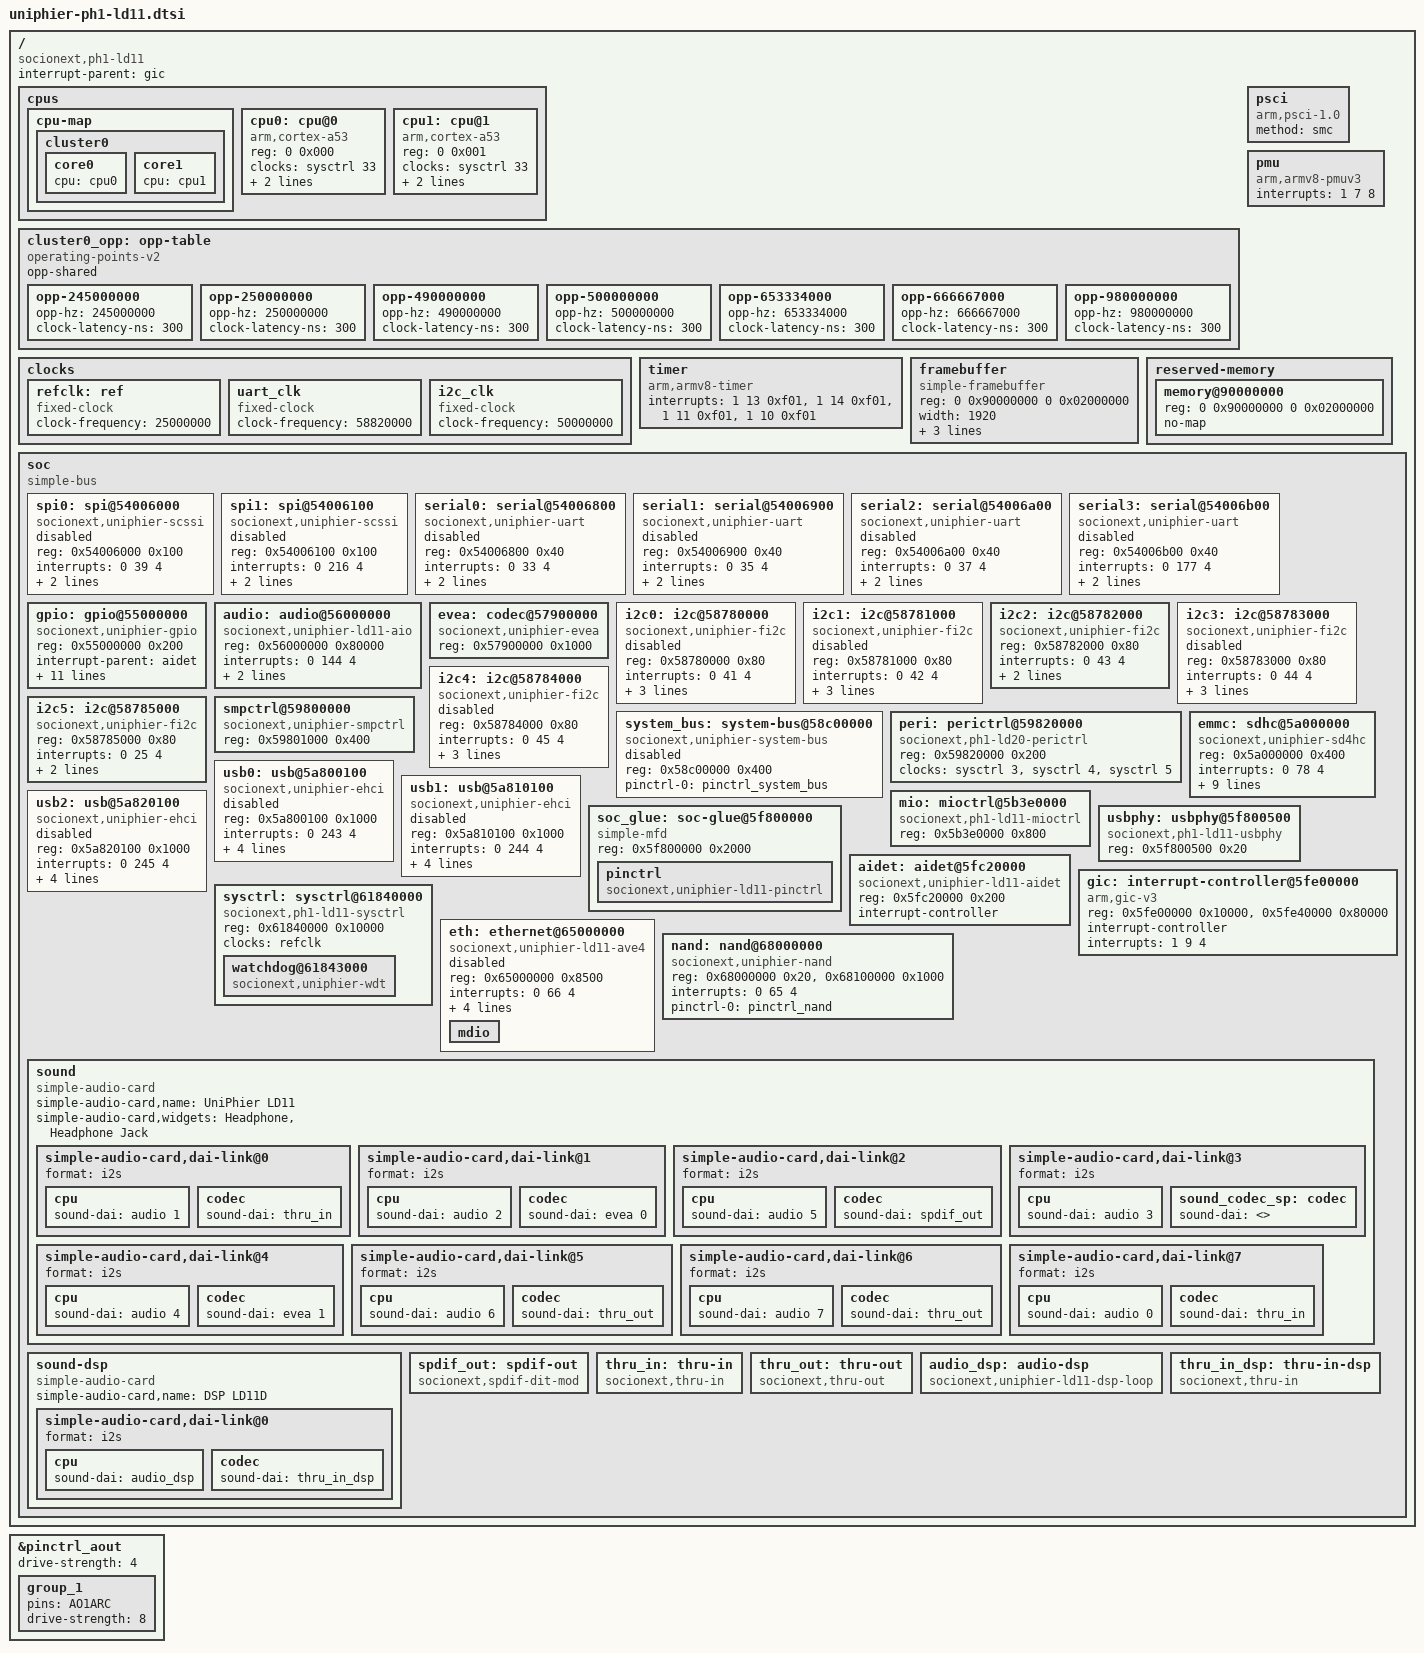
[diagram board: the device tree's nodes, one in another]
// SPDX-Lincense-Identfier: GPL-2.0+ OR MIT
//
// Device Tree Source for UniPhier PH1-LD11 SoC
//
// Copyright (C) 2016 Socionext Inc.
//   Author: Masahiro Yamada <yamada.masahiro@socionext.com>

#include <dt-bindings/gpio/gpio.h>
#include <dt-bindings/gpio/uniphier-gpio.h>

/memreserve/ 0x80000000 0x02000000;

/ {
	compatible = "socionext,ph1-ld11";
	#address-cells = <2>;
	#size-cells = <2>;
	interrupt-parent = <&gic>;

	cpus {
		#address-cells = <2>;
		#size-cells = <0>;

		cpu-map {
			cluster0 {
				core0 {
					cpu = <&cpu0>;
				};
				core1 {
					cpu = <&cpu1>;
				};
			};
		};

		cpu0: cpu@0 {
			device_type = "cpu";
			compatible = "arm,cortex-a53", "arm,armv8";
			reg = <0 0x000>;
			clocks = <&sysctrl 33>;
			enable-method = "psci";
			operating-points-v2 = <&cluster0_opp>;
		};

		cpu1: cpu@1 {
			device_type = "cpu";
			compatible = "arm,cortex-a53", "arm,armv8";
			reg = <0 0x001>;
			clocks = <&sysctrl 33>;
			enable-method = "psci";
			operating-points-v2 = <&cluster0_opp>;
		};
	};

	cluster0_opp: opp-table {
		compatible = "operating-points-v2";
		opp-shared;

		opp-245000000 {
			opp-hz = /bits/ 64 <245000000>;
			clock-latency-ns = <300>;
		};
		opp-250000000 {
			opp-hz = /bits/ 64 <250000000>;
			clock-latency-ns = <300>;
		};
		opp-490000000 {
			opp-hz = /bits/ 64 <490000000>;
			clock-latency-ns = <300>;
		};
		opp-500000000 {
			opp-hz = /bits/ 64 <500000000>;
			clock-latency-ns = <300>;
		};
		opp-653334000 {
			opp-hz = /bits/ 64 <653334000>;
			clock-latency-ns = <300>;
		};
		opp-666667000 {
			opp-hz = /bits/ 64 <666667000>;
			clock-latency-ns = <300>;
		};
		opp-980000000 {
			opp-hz = /bits/ 64 <980000000>;
			clock-latency-ns = <300>;
		};
	};

	psci {
		compatible = "arm,psci-1.0";
		method = "smc";
	};

	clocks {
		refclk: ref {
			#clock-cells = <0>;
			compatible = "fixed-clock";
			clock-frequency = <25000000>;
		};

		uart_clk: uart_clk {
			#clock-cells = <0>;
			compatible = "fixed-clock";
			clock-frequency = <58820000>;
		};

		i2c_clk: i2c_clk {
			#clock-cells = <0>;
			compatible = "fixed-clock";
			clock-frequency = <50000000>;
		};
	};

	timer {
		compatible = "arm,armv8-timer";
		interrupts = <1 13 0xf01>,
			     <1 14 0xf01>,
			     <1 11 0xf01>,
			     <1 10 0xf01>;
	};

	pmu {
		compatible = "arm,armv8-pmuv3";
		interrupts = <1 7 8>;
	};

	framebuffer {
		compatible = "simple-framebuffer";
		reg = <0 0x90000000 0 0x02000000>;
		width = <1920>;
		height = <1088>;
		stride = <7680>;
		format = "a8r8g8b8";
	};

	reserved-memory {
		#address-cells = <2>;
		#size-cells = <2>;
		ranges;

		memory@90000000 {
			reg = <0 0x90000000 0 0x02000000>;
			no-map;
		};
	};

	soc: soc {
		compatible = "simple-bus";
		#address-cells = <1>;
		#size-cells = <1>;
		ranges = <0 0 0 0xffffffff>;

		spi0: spi@54006000 {
			compatible = "socionext,uniphier-scssi";
			status = "disabled";
			reg = <0x54006000 0x100>;
			interrupts = <0 39 4>;
			pinctrl-names = "default";
			pinctrl-0 = <&pinctrl_spi0>;
			clocks = <&peri 11>;
		};

		spi1: spi@54006100 {
			compatible = "socionext,uniphier-scssi";
			status = "disabled";
			reg = <0x54006100 0x100>;
			interrupts = <0 216 4>;
			pinctrl-names = "default";
			pinctrl-0 = <&pinctrl_spi1>;
			clocks = <&peri 11>;
		};

		serial0: serial@54006800 {
			compatible = "socionext,uniphier-uart";
			status = "disabled";
			reg = <0x54006800 0x40>;
			interrupts = <0 33 4>;
			pinctrl-names = "default";
			pinctrl-0 = <&pinctrl_uart0>;
			clocks = <&peri 0>;
		};

		serial1: serial@54006900 {
			compatible = "socionext,uniphier-uart";
			status = "disabled";
			reg = <0x54006900 0x40>;
			interrupts = <0 35 4>;
			pinctrl-names = "default";
			pinctrl-0 = <&pinctrl_uart1>;
			clocks = <&peri 1>;
		};

		serial2: serial@54006a00 {
			compatible = "socionext,uniphier-uart";
			status = "disabled";
			reg = <0x54006a00 0x40>;
			interrupts = <0 37 4>;
			pinctrl-names = "default";
			pinctrl-0 = <&pinctrl_uart2>;
			clocks = <&peri 2>;
		};

		serial3: serial@54006b00 {
			compatible = "socionext,uniphier-uart";
			status = "disabled";
			reg = <0x54006b00 0x40>;
			interrupts = <0 177 4>;
			pinctrl-names = "default";
			pinctrl-0 = <&pinctrl_uart3>;
			clocks = <&peri 3>;
		};

		gpio: gpio@55000000 {
			compatible = "socionext,uniphier-gpio";
			reg = <0x55000000 0x200>;
			interrupt-parent = <&aidet>;
			interrupt-controller;
			#interrupt-cells = <2>;
			gpio-controller;
			#gpio-cells = <2>;
			gpio-ranges = <&pinctrl 0 0 0>,
				      <&pinctrl 43 0 0>,
				      <&pinctrl 51 0 0>,
				      <&pinctrl 96 0 0>,
				      <&pinctrl 160 0 0>,
				      <&pinctrl 184 0 0>;
			gpio-ranges-group-names = "gpio_range0",
						  "gpio_range1",
						  "gpio_range2",
						  "gpio_range3",
						  "gpio_range4",
						  "gpio_range5";
			ngpios = <200>;
			socionext,interrupt-ranges = <0 48 16>, <16 154 5>,
						     <21 217 3>;
		};

		audio: audio@56000000 {
			compatible = "socionext,uniphier-ld11-aio";
			reg = <0x56000000 0x80000>;
			interrupts = <0 144 4>;
			pinctrl-names = "default";
			pinctrl-0 = <&pinctrl_aout>;
			#sound-dai-cells = <1>;
			socionext,syscon = <&soc_glue>;
		};

		evea: codec@57900000 {
			compatible = "socionext,uniphier-evea";
			reg = <0x57900000 0x1000>;
			#sound-dai-cells = <1>;
		};

		i2c0: i2c@58780000 {
			compatible = "socionext,uniphier-fi2c";
			status = "disabled";
			reg = <0x58780000 0x80>;
			#address-cells = <1>;
			#size-cells = <0>;
			interrupts = <0 41 4>;
			pinctrl-names = "default";
			pinctrl-0 = <&pinctrl_i2c0>;
			clocks = <&peri 4>;
			clock-frequency = <100000>;
		};

		i2c1: i2c@58781000 {
			compatible = "socionext,uniphier-fi2c";
			status = "disabled";
			reg = <0x58781000 0x80>;
			#address-cells = <1>;
			#size-cells = <0>;
			interrupts = <0 42 4>;
			pinctrl-names = "default";
			pinctrl-0 = <&pinctrl_i2c1>;
			clocks = <&peri 5>;
			clock-frequency = <100000>;
		};

		i2c2: i2c@58782000 {
			compatible = "socionext,uniphier-fi2c";
			reg = <0x58782000 0x80>;
			#address-cells = <1>;
			#size-cells = <0>;
			interrupts = <0 43 4>;
			clocks = <&peri 6>;
			clock-frequency = <100000>;
		};

		i2c3: i2c@58783000 {
			compatible = "socionext,uniphier-fi2c";
			status = "disabled";
			reg = <0x58783000 0x80>;
			#address-cells = <1>;
			#size-cells = <0>;
			interrupts = <0 44 4>;
			pinctrl-names = "default";
			pinctrl-0 = <&pinctrl_i2c3>;
			clocks = <&peri 7>;
			clock-frequency = <100000>;
		};

		i2c4: i2c@58784000 {
			compatible = "socionext,uniphier-fi2c";
			status = "disabled";
			reg = <0x58784000 0x80>;
			#address-cells = <1>;
			#size-cells = <0>;
			interrupts = <0 45 4>;
			pinctrl-names = "default";
			pinctrl-0 = <&pinctrl_i2c4>;
			clocks = <&peri 8>;
			clock-frequency = <100000>;
		};

		i2c5: i2c@58785000 {
			compatible = "socionext,uniphier-fi2c";
			reg = <0x58785000 0x80>;
			#address-cells = <1>;
			#size-cells = <0>;
			interrupts = <0 25 4>;
			clocks = <&peri 9>;
			clock-frequency = <400000>;
		};

		system_bus: system-bus@58c00000 {
			compatible = "socionext,uniphier-system-bus";
			status = "disabled";
			reg = <0x58c00000 0x400>;
			#address-cells = <2>;
			#size-cells = <1>;
			pinctrl-names = "default";
			pinctrl-0 = <&pinctrl_system_bus>;
		};

		smpctrl@59800000 {
			compatible = "socionext,uniphier-smpctrl";
			reg = <0x59801000 0x400>;
		};

		peri: perictrl@59820000 {
			compatible = "socionext,ph1-ld20-perictrl";
			reg = <0x59820000 0x200>;
			#clock-cells = <1>;
			clock-names = "uart", "fi2c", "spi";
			clocks = <&sysctrl 3>, <&sysctrl 4>, <&sysctrl 5>;
		};

		emmc: sdhc@5a000000 {
			compatible = "socionext,uniphier-sd4hc", "cdns,sd4hc";
			reg = <0x5a000000 0x400>;
			interrupts = <0 78 4>;
			pinctrl-names = "default";
			pinctrl-0 = <&pinctrl_emmc_1v8>;
			clocks = <&refclk>; /* fake */
			bus-width = <8>;
			mmc-hs200-1_8v;
			cdns,phy-input-delay-legacy = <9>;
			cdns,phy-input-delay-mmc-highspeed = <2>;
			cdns,phy-input-delay-mmc-ddr = <3>;
			cdns,phy-dll-delay-sdclk = <21>;
			cdns,phy-dll-delay-sdclk-hsmmc = <21>;
		};

		usb0: usb@5a800100 {
			compatible = "socionext,uniphier-ehci", "generic-ehci";
			status = "disabled";
			reg = <0x5a800100 0x1000>;
			interrupts = <0 243 4>;
			pinctrl-names = "default";
			pinctrl-0 = <&pinctrl_usb0>;
			clocks = <&mio 4>, <&mio 8>, <&sysctrl 22>;
			phys = <&usbphy>;
			phy-names = "usb";
			has-transaction-translator;
		};

		usb1: usb@5a810100 {
			compatible = "socionext,uniphier-ehci", "generic-ehci";
			status = "disabled";
			reg = <0x5a810100 0x1000>;
			interrupts = <0 244 4>;
			pinctrl-names = "default";
			pinctrl-0 = <&pinctrl_usb1>;
			clocks = <&mio 5>, <&mio 8>, <&sysctrl 22>;
			phys = <&usbphy>;
			phy-names = "usb";
			has-transaction-translator;
		};

		usb2: usb@5a820100 {
			compatible = "socionext,uniphier-ehci", "generic-ehci";
			status = "disabled";
			reg = <0x5a820100 0x1000>;
			interrupts = <0 245 4>;
			pinctrl-names = "default";
			pinctrl-0 = <&pinctrl_usb2>;
			clocks = <&mio 6>, <&mio 8>, <&sysctrl 23>;
			phys = <&usbphy>;
			phy-names = "usb";
			has-transaction-translator;
		};

		mio: mioctrl@5b3e0000 {
			compatible = "socionext,ph1-ld11-mioctrl";
			reg = <0x5b3e0000 0x800>;
			#clock-cells = <1>;
		};

		soc_glue: soc-glue@5f800000 {
			compatible = "simple-mfd", "syscon";
			reg = <0x5f800000 0x2000>;

			pinctrl: pinctrl {
				 compatible = "socionext,uniphier-ld11-pinctrl";
			};
		};

		usbphy: usbphy@5f800500 {
			#phy-cells = <0>;
			compatible = "socionext,ph1-ld11-usbphy";
			reg = <0x5f800500 0x20>;
		};

		aidet: aidet@5fc20000 {
			compatible = "socionext,uniphier-ld11-aidet";
			reg = <0x5fc20000 0x200>;
			interrupt-controller;
			#interrupt-cells = <2>;
		};

		gic: interrupt-controller@5fe00000 {
			compatible = "arm,gic-v3";
			reg = <0x5fe00000 0x10000>,	/* GICD */
			      <0x5fe40000 0x80000>;	/* GICR */
			interrupt-controller;
			#interrupt-cells = <3>;
			interrupts = <1 9 4>;
		};

		sysctrl: sysctrl@61840000 {
			compatible = "socionext,ph1-ld11-sysctrl",
				     "simple-mfd", "syscon";
			reg = <0x61840000 0x10000>;
			#clock-cells = <1>;
			clock-names = "ref";
			clocks = <&refclk>;

			watchdog@61843000 {
				compatible = "socionext,uniphier-wdt";
			};
		};

		eth: ethernet@65000000 {
			compatible = "socionext,uniphier-ld11-ave4";
			status = "disabled";
			reg = <0x65000000 0x8500>;
			interrupts = <0 66 4>;
			clock-names = "ether";
			clocks = <&sysctrl 8>;
			phy-mode = "internal";
			local-mac-address = [00 00 00 00 00 00];
			socionext,syscon-phy-mode = <&soc_glue 0>;

			mdio: mdio {
				#address-cells = <1>;
				#size-cells = <0>;
			};
		};

		nand: nand@68000000 {
			compatible = "socionext,uniphier-nand";
			reg = <0x68000000 0x20>, <0x68100000 0x1000>;
			reg-names = "nand_data", "nand_reg";
			interrupts = <0 65 4>;
			pinctrl-names = "default";
			pinctrl-0 = <&pinctrl_nand>;
		};

		sound {
			compatible = "simple-audio-card";
			simple-audio-card,name = "UniPhier LD11";
			simple-audio-card,widgets = "Headphone", "Headphone Jack";

			simple-audio-card,dai-link@0 {
				/* SIF in 1 */
				format = "i2s";
				cpu {
					sound-dai = <&audio 1>;
				};
				codec {
					sound-dai = <&thru_in>;
				};
			};
			simple-audio-card,dai-link@1 {
				/* Line in/out 1 */
				format = "i2s";
				cpu {
					sound-dai = <&audio 2>;
				};
				codec {
					sound-dai = <&evea 0>;
				};
			};
			simple-audio-card,dai-link@2 {
				/* SPDIF */
				format = "i2s";
				cpu {
					sound-dai = <&audio 5>;
				};
				codec {
					sound-dai = <&spdif_out>;
				};
			};
			simple-audio-card,dai-link@3 {
				/* Speaker */
				format = "i2s";
				cpu {
					sound-dai = <&audio 3>;
				};
				sound_codec_sp: codec {
					/* external codec */
					sound-dai = <>;
				};
			};
			simple-audio-card,dai-link@4 {
				/* Headphone */
				format = "i2s";
				cpu {
					sound-dai = <&audio 4>;
				};
				codec {
					sound-dai = <&evea 1>;
				};
			};
			simple-audio-card,dai-link@5 {
				/* SRC0 */
				format = "i2s";
				cpu {
					sound-dai = <&audio 6>;
				};
				codec {
					sound-dai = <&thru_out>;
				};
			};
			simple-audio-card,dai-link@6 {
				/* SRC1 */
				format = "i2s";
				cpu {
					sound-dai = <&audio 7>;
				};
				codec {
					sound-dai = <&thru_out>;
				};
			};
			simple-audio-card,dai-link@7 {
				/* HDMI in/out */
				format = "i2s";
				cpu {
					sound-dai = <&audio 0>;
				};
				codec {
					sound-dai = <&thru_in>;
				};
			};
		};

		sound-dsp {
			compatible = "simple-audio-card";
			simple-audio-card,name = "DSP LD11D";

			simple-audio-card,dai-link@0 {
				/* BT in */
				format = "i2s";
				cpu {
					sound-dai = <&audio_dsp>;
				};
				codec {
					sound-dai = <&thru_in_dsp>;
				};
			};
		};

		spdif_out: spdif-out {
			compatible = "socionext,spdif-dit-mod";
			#sound-dai-cells = <0>;
		};

		thru_in: thru-in {
			compatible = "socionext,thru-in";
			#sound-dai-cells = <0>;
		};

		thru_out: thru-out {
			compatible = "socionext,thru-out";
			#sound-dai-cells = <0>;
		};

		audio_dsp: audio-dsp {
			compatible = "socionext,uniphier-ld11-dsp-loop";
			#sound-dai-cells = <0>;
		};

		thru_in_dsp: thru-in-dsp {
			compatible = "socionext,thru-in";
			#sound-dai-cells = <0>;
		};
	};
};

#include "uniphier-pinctrl.dtsi"

&pinctrl_aout {
	drive-strength = <4>;	/* default: 4mA */
	group_1 {
		pins = "AO1ARC";
		drive-strength = <8>;	/* 8mA */
	};
};
